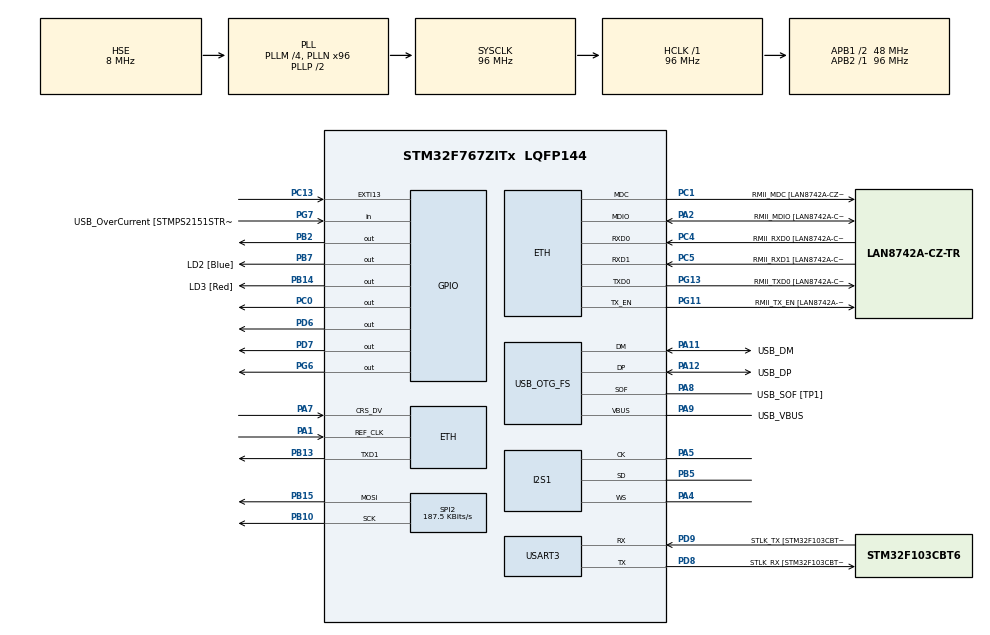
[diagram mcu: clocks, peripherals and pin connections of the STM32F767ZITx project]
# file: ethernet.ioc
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CORTEX_M7.AccessPermission-Cortex_Memory_Protection_Unit_Region0_Settings=MPU_REGION_FULL_ACCESS
CORTEX_M7.BaseAddress-Cortex_Memory_Protection_Unit_Region0_Settings=0x2007c000
CORTEX_M7.DisableExec-Cortex_Memory_Protection_Unit_Region0_Settings=MPU_INSTRUCTION_ACCESS_DISABLE
CORTEX_M7.Enable-Cortex_Memory_Protection_Unit_Region0_Settings=MPU_REGION_ENABLE
CORTEX_M7.FlashInterface=TCM_Enabled
CORTEX_M7.IsShareable-Cortex_Memory_Protection_Unit_Region0_Settings=MPU_ACCESS_SHAREABLE
CORTEX_M7.MPU_Control=MPU_HFNMI_PRIVDEF
CORTEX_M7.Size-Cortex_Memory_Protection_Unit_Region0_Settings=MPU_REGION_SIZE_16KB
CORTEX_M7.TypeExtField-Cortex_Memory_Protection_Unit_Region0_Settings=MPU_TEX_LEVEL1
ETH.MediaInterface=HAL_ETH_RMII_MODE
FREERTOS.Tasks01=defaultTask,24,256,StartDefaultTask,Default,NULL,Dynamic,NULL,NULL
FREERTOS.configUSE_NEWLIB_REENTRANT=1
I2S1.AudioFreq=I2S_AUDIOFREQ_48K
I2S1.DataFormat=I2S_DATAFORMAT_24B
I2S1.ErrorAudioFreq=-0.79 %
I2S1.FullDuplexMode=I2S_FULLDUPLEXMODE_DISABLE
I2S1.Instance=SPI$Index
I2S1.Mode=I2S_MODE_MASTER_RX
I2S1.RealAudioFreq=47.619 KHz
I2S1.VirtualMode=I2S_MODE_MASTER
Mcu.Family=STM32F7
Mcu.Name=STM32F767ZITx
Mcu.Package=LQFP144
NVIC.PriorityGroup=NVIC_PRIORITYGROUP_4
NVIC.TIM6_DAC_IRQn=true\:15\:0\:false\:false\:true\:false\:false\:true\:true
NVIC.TimeBase=TIM6_DAC_IRQn
NVIC.TimeBaseIP=TIM6
PA1.Mode=RMII
PA1.Signal=ETH_REF_CLK
PA10.GPIO_Label=USB_ID
PA10.Signal=USB_OTG_FS_ID
PA11.GPIO_Label=USB_DM
PA11.Mode=Device_Only
PA11.Signal=USB_OTG_FS_DM
PA12.GPIO_Label=USB_DP
PA12.Mode=Device_Only
PA12.Signal=USB_OTG_FS_DP
PA13.GPIO_Label=TMS
PA13.Mode=Serial_Wire
PA13.Signal=SYS_JTMS-SWDIO
PA14.GPIO_Label=TCK
PA14.Mode=Serial_Wire
PA14.Signal=SYS_JTCK-SWCLK
PA2.GPIO_Label=RMII_MDIO [LAN8742A-CZ-TR_MDIO]
PA2.Mode=RMII
PA2.Signal=ETH_MDIO
PA3.Signal=ETH_COL
PA4.Mode=Half_Duplex_Master
PA4.Signal=I2S1_WS
PA5.Mode=Half_Duplex_Master
PA5.Signal=I2S1_CK
PA7.Mode=RMII
PA7.Signal=ETH_CRS_DV
PA8.GPIO_Label=USB_SOF [TP1]
PA8.Mode=Activate_SOF_FS
PA8.Signal=USB_OTG_FS_SOF
PA9.GPIO_Label=USB_VBUS
PA9.Mode=Activate_VBUS
PA9.Signal=USB_OTG_FS_VBUS
PB0.Signal=ETH_RXD2
PB10.Mode=TX_Only_Simplex_Unidirect_Master
PB10.Signal=SPI2_SCK
PB13.Mode=RMII
PB13.Signal=ETH_TXD1
PB14.GPIO_Label=LD3 [Red]
PB14.Signal=GPIO_Output
PB15.Mode=TX_Only_Simplex_Unidirect_Master
PB15.Signal=SPI2_MOSI
PB2.GPIO_Speed=GPIO_SPEED_FREQ_VERY_HIGH
PB2.PinState=GPIO_PIN_SET
PB2.Signal=GPIO_Output
PB3.GPIO_Label=SWO
PB3.Signal=SYS_JTDO-SWO
PB5.Mode=Half_Duplex_Master
PB5.Signal=I2S1_SD
PB7.GPIO_Label=LD2 [Blue]
PB7.Signal=GPIO_Output
PC0.GPIO_Speed=GPIO_SPEED_FREQ_VERY_HIGH
PC0.Signal=GPIO_Output
PC1.GPIO_Label=RMII_MDC [LAN8742A-CZ-TR_MDC]
PC1.Mode=RMII
PC1.Signal=ETH_MDC
PC13.Signal=GPXTI13
PC14/OSC32_IN.Mode=LSE-External-Oscillator
PC14/OSC32_IN.Signal=RCC_OSC32_IN
PC15/OSC32_OUT.Mode=LSE-External-Oscillator
PC15/OSC32_OUT.Signal=RCC_OSC32_OUT
PC3.Signal=ETH_TX_CLK
PC4.GPIO_Label=RMII_RXD0 [LAN8742A-CZ-TR_RXD0]
PC4.Mode=RMII
PC4.Signal=ETH_RXD0
PC5.GPIO_Label=RMII_RXD1 [LAN8742A-CZ-TR_RXD1]
PC5.Mode=RMII
PC5.Signal=ETH_RXD1
PD6.GPIO_Speed=GPIO_SPEED_FREQ_VERY_HIGH
PD6.Signal=GPIO_Output
PD7.GPIO_Speed=GPIO_SPEED_FREQ_VERY_HIGH
PD7.Signal=GPIO_Output
PD8.GPIO_Label=STLK_RX [STM32F103CBT6_PA3]
PD8.Mode=Asynchronous
PD8.Signal=USART3_TX
PD9.GPIO_Label=STLK_TX [STM32F103CBT6_PA2]
PD9.Mode=Asynchronous
PD9.Signal=USART3_RX
PG11.GPIO_Label=RMII_TX_EN [LAN8742A-CZ-TR_TXEN]
PG11.Mode=RMII
PG11.Signal=ETH_TX_EN
PG13.GPIO_Label=RMII_TXD0 [LAN8742A-CZ-TR_TXD0]
PG13.Mode=RMII
PG13.Signal=ETH_TXD0
PG6.Signal=GPIO_Output
PG7.GPIO_Label=USB_OverCurrent [STMPS2151STR_FAULT]
PG7.Signal=GPIO_Input
PH0/OSC_IN.GPIO_Label=MCO [STM32F103CBT6_PA8]
PH0/OSC_IN.Mode=HSE-External-Clock-Source
PH0/OSC_IN.Signal=RCC_OSC_IN
PH1/OSC_OUT.Mode=HSE-External-Clock-Source
PH1/OSC_OUT.Signal=RCC_OSC_OUT
ProjectManager.HeapSize=0x200
ProjectManager.StackSize=0x400
ProjectManager.TargetToolchain=STM32CubeIDE
RCC.48MHZClocksFreq_Value=24000000
RCC.AHBFreq_Value=96000000
RCC.APB1CLKDivider=RCC_HCLK_DIV2
RCC.APB1Freq_Value=48000000
RCC.APB1TimFreq_Value=96000000
RCC.APB2Freq_Value=96000000
RCC.APB2TimFreq_Value=96000000
RCC.CortexFreq_Value=96000000
RCC.HCLKFreq_Value=96000000
RCC.HSE_VALUE=8000000
RCC.HSI_VALUE=16000000
RCC.PLLM=4
RCC.PLLMUL=RCC_PLL_MUL9
RCC.PLLN=96
RCC.PLLQ=4
RCC.PRESCALERUSB=RCC_USBCLKSOURCE_PLL_DIV1_5
RCC.SYSCLKFreq_VALUE=96000000
RCC.SYSCLKSource=RCC_SYSCLKSOURCE_PLLCLK
RCC.SYSCLKSourceVirtual=RCC_SYSCLKSOURCE_PLLCLK
RCC.USBFreq_Value=48000000
RCC.VCOOutputFreq_Value=192000000
SPI2.BaudRatePrescaler=SPI_BAUDRATEPRESCALER_256
SPI2.CLKPhase=SPI_PHASE_1EDGE
SPI2.CLKPolarity=SPI_POLARITY_HIGH
SPI2.CalculateBaudRate=187.5 KBits/s
SPI2.DataSize=SPI_DATASIZE_8BIT
SPI2.Direction=SPI_DIRECTION_2LINES
SPI2.Mode=SPI_MODE_MASTER
SPI2.NSSPMode=SPI_NSS_PULSE_DISABLE
SPI2.VirtualType=VM_MASTER
USART3.VirtualMode-Asynchronous=VM_ASYNC
USB_OTG_FS.VirtualMode=Device_Only
VP_FREERTOS_VS_CMSIS_V2.Mode=CMSIS_V2
VP_RNG_VS_RNG.Mode=RNG_Activate
VP_SYS_VS_tim6.Mode=TIM6
board=NUCLEO-F767ZI

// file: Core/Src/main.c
/* USER CODE BEGIN Header */
/**
  ******************************************************************************
  * @file           : main.c
  * @brief          : Main program body
  ******************************************************************************
  * @attention
  *
  * Copyright (c) 2025 STMicroelectronics.
  * All rights reserved.
  *
  * This software is licensed under terms that can be found in the LICENSE file
  * in the root directory of this software component.
  * If no LICENSE file comes with this software, it is provided AS-IS.
  *
  ******************************************************************************
  */
/* USER CODE END Header */
#include "main.h"
#include "cmsis_os.h"
#include "eth.h"
#include "i2s.h"
#include "rng.h"
#include "spi.h"
#include "usart.h"
#include "usb_otg.h"
#include "gpio.h"

/* USER CODE BEGIN Includes */
#include "app_main.h"
#include "TCP_IP.h"
/* USER CODE END Includes */

void SystemClock_Config(void);
static void MPU_Config(void);
void MX_FREERTOS_Init(void);
/* USER CODE BEGIN PFP */
#define PUTCHAR_PROTOTYPE int __io_putchar(int ch)
/* USER CODE END PFP */

int main(void)
{

  /* MPU Configuration--------------------------------------------------------*/
  MPU_Config();

  /* MCU Configuration--------------------------------------------------------*/

  /* Reset of all peripherals, Initializes the Flash interface and the Systick. */
  HAL_Init();

  /* Configure the system clock */
  SystemClock_Config();

  /* Initialize all configured peripherals */
  MX_GPIO_Init();
  MX_USART3_UART_Init();
  MX_USB_OTG_FS_PCD_Init();
  MX_SPI2_Init();
  MX_RNG_Init();
  MX_I2S1_Init();
  MX_ETH_Init();

  /* Init scheduler */
  osKernelInitialize();  /* Call init function for freertos objects (in cmsis_os2.c) */
  MX_FREERTOS_Init();

  /* Start scheduler */
  osKernelStart();

  /* We should never get here as control is now taken by the scheduler */

  /* Infinite loop */
  while (1)
  {

    /* USER CODE BEGIN 3 */

	  AppMain();
  }
  /* USER CODE END 3 */
}

void SystemClock_Config(void)
{
  RCC_OscInitTypeDef RCC_OscInitStruct = {0};
  RCC_ClkInitTypeDef RCC_ClkInitStruct = {0};

  /** Configure LSE Drive Capability
  */
  HAL_PWR_EnableBkUpAccess();

  /** Configure the main internal regulator output voltage
  */
  __HAL_RCC_PWR_CLK_ENABLE();
  __HAL_PWR_VOLTAGESCALING_CONFIG(PWR_REGULATOR_VOLTAGE_SCALE3);

  /** Initializes the RCC Oscillators according to the specified parameters
  * in the RCC_OscInitTypeDef structure.
  */
  RCC_OscInitStruct.OscillatorType = RCC_OSCILLATORTYPE_HSE;
  RCC_OscInitStruct.HSEState = RCC_HSE_BYPASS;
  RCC_OscInitStruct.PLL.PLLState = RCC_PLL_ON;
  RCC_OscInitStruct.PLL.PLLSource = RCC_PLLSOURCE_HSE;
  RCC_OscInitStruct.PLL.PLLM = 4;
  RCC_OscInitStruct.PLL.PLLN = 96;
  RCC_OscInitStruct.PLL.PLLP = RCC_PLLP_DIV2;
  RCC_OscInitStruct.PLL.PLLQ = 4;
  RCC_OscInitStruct.PLL.PLLR = 2;
  if (HAL_RCC_OscConfig(&RCC_OscInitStruct) != HAL_OK)
  {
    Error_Handler();
  }

  /** Activate the Over-Drive mode
  */
  if (HAL_PWREx_EnableOverDrive() != HAL_OK)
  {
    Error_Handler();
  }

  /** Initializes the CPU, AHB and APB buses clocks
  */
  RCC_ClkInitStruct.ClockType = RCC_CLOCKTYPE_HCLK|RCC_CLOCKTYPE_SYSCLK
                              |RCC_CLOCKTYPE_PCLK1|RCC_CLOCKTYPE_PCLK2;
  RCC_ClkInitStruct.SYSCLKSource = RCC_SYSCLKSOURCE_PLLCLK;
  RCC_ClkInitStruct.AHBCLKDivider = RCC_SYSCLK_DIV1;
  RCC_ClkInitStruct.APB1CLKDivider = RCC_HCLK_DIV2;
  RCC_ClkInitStruct.APB2CLKDivider = RCC_HCLK_DIV1;

  if (HAL_RCC_ClockConfig(&RCC_ClkInitStruct, FLASH_LATENCY_3) != HAL_OK)
  {
    Error_Handler();
  }
}

 /* MPU Configuration */

void MPU_Config(void)
{
  MPU_Region_InitTypeDef MPU_InitStruct = {0};

  /* Disables the MPU */
  HAL_MPU_Disable();

  /** Initializes and configures the Region and the memory to be protected
  */
  MPU_InitStruct.Enable = MPU_REGION_ENABLE;
  MPU_InitStruct.Number = MPU_REGION_NUMBER0;
  MPU_InitStruct.BaseAddress = 0x2007c000;
  MPU_InitStruct.Size = MPU_REGION_SIZE_16KB;
  MPU_InitStruct.SubRegionDisable = 0x0;
  MPU_InitStruct.TypeExtField = MPU_TEX_LEVEL1;
  MPU_InitStruct.AccessPermission = MPU_REGION_FULL_ACCESS;
  MPU_InitStruct.DisableExec = MPU_INSTRUCTION_ACCESS_DISABLE;
  MPU_InitStruct.IsShareable = MPU_ACCESS_SHAREABLE;
  MPU_InitStruct.IsCacheable = MPU_ACCESS_NOT_CACHEABLE;
  MPU_InitStruct.IsBufferable = MPU_ACCESS_NOT_BUFFERABLE;

  HAL_MPU_ConfigRegion(&MPU_InitStruct);
  /* Enables the MPU */
  HAL_MPU_Enable(MPU_HFNMI_PRIVDEF);

}

void HAL_TIM_PeriodElapsedCallback(TIM_HandleTypeDef *htim)
{
  if (htim->Instance == TIM6)
  {
    HAL_IncTick();
  }
}

void Error_Handler(void)
{
  __disable_irq();
  while (1)
  {
  }
}

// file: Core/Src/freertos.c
/* USER CODE BEGIN Header */
/**
  ******************************************************************************
  * File Name          : freertos.c
  * Description        : Code for freertos applications
  ******************************************************************************
  * @attention
  *
  * Copyright (c) 2025 STMicroelectronics.
  * All rights reserved.
  *
  * This software is licensed under terms that can be found in the LICENSE file
  * in the root directory of this software component.
  * If no LICENSE file comes with this software, it is provided AS-IS.
  *
  ******************************************************************************
  */
/* USER CODE END Header */

#include "FreeRTOS.h"
#include "task.h"
#include "main.h"
#include "cmsis_os.h"

/* USER CODE BEGIN Includes */
#include "app_main.h"
/* USER CODE END Includes */

/* Definitions for defaultTask */
osThreadId_t defaultTaskHandle;
const osThreadAttr_t defaultTask_attributes = {
  .name = "defaultTask",
  .stack_size = 256 * 4,
  .priority = (osPriority_t) osPriorityNormal,
};

void StartDefaultTask(void *argument);

void MX_FREERTOS_Init(void); /* (MISRA C 2004 rule 8.1) */

void MX_FREERTOS_Init(void) {

  /* Create the thread(s) */
  /* creation of defaultTask */
  defaultTaskHandle = osThreadNew(StartDefaultTask, NULL, &defaultTask_attributes);

}

void StartDefaultTask(void *argument)
{
  /* USER CODE BEGIN StartDefaultTask */
  /* Infinite loop */
  for(;;)
  {
	 AppMain();
    osDelay(1);
  }
  /* USER CODE END StartDefaultTask */
}
